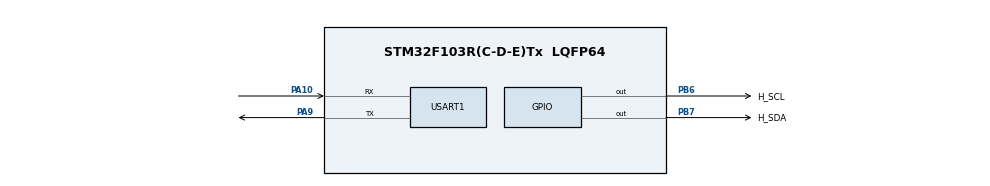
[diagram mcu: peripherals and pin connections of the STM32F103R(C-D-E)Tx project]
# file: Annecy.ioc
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Mcu.Family=STM32F1
Mcu.Name=STM32F103R(C-D-E)Tx
Mcu.Package=LQFP64
NVIC.PriorityGroup=NVIC_PRIORITYGROUP_4
PA10.Mode=Asynchronous
PA10.Signal=USART1_RX
PA13.Mode=Serial_Wire
PA13.Signal=SYS_JTMS-SWDIO
PA14.Mode=Serial_Wire
PA14.Signal=SYS_JTCK-SWCLK
PA9.Mode=Asynchronous
PA9.Signal=USART1_TX
PB6.GPIO_Label=H_SCL
PB6.GPIO_Speed=GPIO_SPEED_FREQ_HIGH
PB6.PinState=GPIO_PIN_SET
PB6.Signal=GPIO_Output
PB7.GPIO_Label=H_SDA
PB7.GPIO_Speed=GPIO_SPEED_FREQ_HIGH
PB7.PinState=GPIO_PIN_SET
PB7.Signal=GPIO_Output
PC14-OSC32_IN.Mode=LSE-External-Oscillator
PC14-OSC32_IN.Signal=RCC_OSC32_IN
PC15-OSC32_OUT.Mode=LSE-External-Oscillator
PC15-OSC32_OUT.Signal=RCC_OSC32_OUT
PD0-OSC_IN.Mode=HSE-External-Oscillator
PD0-OSC_IN.Signal=RCC_OSC_IN
PD1-OSC_OUT.Mode=HSE-External-Oscillator
PD1-OSC_OUT.Signal=RCC_OSC_OUT
ProjectManager.HeapSize=0x200
ProjectManager.StackSize=0x400
ProjectManager.TargetToolchain=MDK-ARM V5
RCC.APB1Freq_Value=8000000
RCC.APB2Freq_Value=8000000
RCC.SYSCLKSource=RCC_SYSCLKSOURCE_PLLCLK
board=Annecy

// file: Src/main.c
/**
  ******************************************************************************
  * File Name          : main.c
  * Description        : Main program body
  ******************************************************************************
  *
  * COPYRIGHT(c) 2017 STMicroelectronics
  *
  * Redistribution and use in source and binary forms, with or without modification,
  * are permitted provided that the following conditions are met:
  *   1. Redistributions of source code must retain the above copyright notice,
  *      this list of conditions and the following disclaimer.
  *   2. Redistributions in binary form must reproduce the above copyright notice,
  *      this list of conditions and the following disclaimer in the documentation
  *      and/or other materials provided with the distribution.
  *   3. Neither the name of STMicroelectronics nor the names of its contributors
  *      may be used to endorse or promote products derived from this software
  *      without specific prior written permission.
  *
  * THIS SOFTWARE IS PROVIDED BY THE COPYRIGHT HOLDERS AND CONTRIBUTORS "AS IS"
  * AND ANY EXPRESS OR IMPLIED WARRANTIES, INCLUDING, BUT NOT LIMITED TO, THE
  * IMPLIED WARRANTIES OF MERCHANTABILITY AND FITNESS FOR A PARTICULAR PURPOSE ARE
  * DISCLAIMED. IN NO EVENT SHALL THE COPYRIGHT HOLDER OR CONTRIBUTORS BE LIABLE
  * FOR ANY DIRECT, INDIRECT, INCIDENTAL, SPECIAL, EXEMPLARY, OR CONSEQUENTIAL
  * DAMAGES (INCLUDING, BUT NOT LIMITED TO, PROCUREMENT OF SUBSTITUTE GOODS OR
  * SERVICES; LOSS OF USE, DATA, OR PROFITS; OR BUSINESS INTERRUPTION) HOWEVER
  * CAUSED AND ON ANY THEORY OF LIABILITY, WHETHER IN CONTRACT, STRICT LIABILITY,
  * OR TORT (INCLUDING NEGLIGENCE OR OTHERWISE) ARISING IN ANY WAY OUT OF THE USE
  * OF THIS SOFTWARE, EVEN IF ADVISED OF THE POSSIBILITY OF SUCH DAMAGE.
  *
  ******************************************************************************
  */
#include "main.h"
#include "stm32f1xx_hal.h"

UART_HandleTypeDef huart1;

/* USER CODE BEGIN PV */
/* Private variables ---------------------------------------------------------*/
#ifdef __GNUC__
/* With GCC, small printf (option LD Linker->Libraries->Small printf
   set to 'Yes') calls __io_putchar() */
#define PUTCHAR_PROTOTYPE int __io_putchar(int ch)
#else
#define PUTCHAR_PROTOTYPE int fputc(int ch, FILE *f)
#endif /* __GNUC__ */
/* USER CODE END PV */

void SystemClock_Config(void);
void Error_Handler(void);
static void MX_GPIO_Init(void);
static void MX_USART1_UART_Init(void);

/* USER CODE BEGIN PFP */
/* Private function prototypes -----------------------------------------------*/
uint16_t temp = 0;
/* USER CODE END PFP */

int main(void)
{

  /* USER CODE BEGIN 1 */
	uint32_t en = 0 ;
	uint32_t sw = 0 ;
  /* USER CODE END 1 */

  /* MCU Configuration----------------------------------------------------------*/

  /* Reset of all peripherals, Initializes the Flash interface and the Systick. */
  HAL_Init();

  /* Configure the system clock */
  SystemClock_Config();

  /* Initialize all configured peripherals */
  MX_GPIO_Init();
  MX_USART1_UART_Init();
	DWT_Init();
//	en = DWT_Get();
//	Delay_us(20);
//	sw = DWT_Get();
//	printf("time=%d\r\n ",(sw - en ));
  /* USER CODE BEGIN 2 */
	printf("hello, world\r\n");
	hdcWriting(0xAA,0xAA,0xAA,0x00);
	hdcWriting(0x40,0x02,0x90,0x00);
//	temp = hdcReading(0x40,0xFB);
//	HAL_Delay(200);
//
//	temp = 0x1521;
//	printf("temp = %x",temp);
  /* USER CODE END 2 */

  /* Infinite loop */
  while (1)
  {

  }

}

/**
  * @brief  Retargets the C library printf function to the USART.
  * @param  None
  * @retval None
  */
PUTCHAR_PROTOTYPE
{
  /* Place your implementation of fputc here */
  /* e.g. write a character to the USART1 and Loop until the end of transmission */
  HAL_UART_Transmit(&huart1, (uint8_t *)&ch, 1, 0xFFFF);

  return ch;
}

/** System Clock Configuration
*/
void SystemClock_Config(void)
{

  RCC_OscInitTypeDef RCC_OscInitStruct;
  RCC_ClkInitTypeDef RCC_ClkInitStruct;

    /**Initializes the CPU, AHB and APB busses clocks
    */
  RCC_OscInitStruct.OscillatorType = RCC_OSCILLATORTYPE_HSI;
  RCC_OscInitStruct.HSIState = RCC_HSI_ON;
  RCC_OscInitStruct.HSICalibrationValue = 16;
  RCC_OscInitStruct.PLL.PLLState = RCC_PLL_ON;
  RCC_OscInitStruct.PLL.PLLSource = RCC_PLLSOURCE_HSI_DIV2;
  RCC_OscInitStruct.PLL.PLLMUL = RCC_PLL_MUL2;
  if (HAL_RCC_OscConfig(&RCC_OscInitStruct) != HAL_OK)
  {
    Error_Handler();
  }

    /**Initializes the CPU, AHB and APB busses clocks
    */
  RCC_ClkInitStruct.ClockType = RCC_CLOCKTYPE_HCLK|RCC_CLOCKTYPE_SYSCLK
                              |RCC_CLOCKTYPE_PCLK1|RCC_CLOCKTYPE_PCLK2;
  RCC_ClkInitStruct.SYSCLKSource = RCC_SYSCLKSOURCE_PLLCLK;
  RCC_ClkInitStruct.AHBCLKDivider = RCC_SYSCLK_DIV1;
  RCC_ClkInitStruct.APB1CLKDivider = RCC_HCLK_DIV1;
  RCC_ClkInitStruct.APB2CLKDivider = RCC_HCLK_DIV1;

  if (HAL_RCC_ClockConfig(&RCC_ClkInitStruct, FLASH_LATENCY_0) != HAL_OK)
  {
    Error_Handler();
  }

    /**Configure the Systick interrupt time
    */
  HAL_SYSTICK_Config(HAL_RCC_GetHCLKFreq()/1000);

    /**Configure the Systick
    */
  HAL_SYSTICK_CLKSourceConfig(SYSTICK_CLKSOURCE_HCLK);

  /* SysTick_IRQn interrupt configuration */
  HAL_NVIC_SetPriority(SysTick_IRQn, 0, 0);
}

/* USART1 init function */
static void MX_USART1_UART_Init(void)
{

  huart1.Instance = USART1;
  huart1.Init.BaudRate = 115200;
  huart1.Init.WordLength = UART_WORDLENGTH_8B;
  huart1.Init.StopBits = UART_STOPBITS_1;
  huart1.Init.Parity = UART_PARITY_NONE;
  huart1.Init.Mode = UART_MODE_TX_RX;
  huart1.Init.HwFlowCtl = UART_HWCONTROL_NONE;
  huart1.Init.OverSampling = UART_OVERSAMPLING_16;
  if (HAL_UART_Init(&huart1) != HAL_OK)
  {
    Error_Handler();
  }

}

/** Configure pins as
        * Analog
        * Input
        * Output
        * EVENT_OUT
        * EXTI
*/
static void MX_GPIO_Init(void)
{

  GPIO_InitTypeDef GPIO_InitStruct;

  /* GPIO Ports Clock Enable */
  __HAL_RCC_GPIOC_CLK_ENABLE();
  __HAL_RCC_GPIOD_CLK_ENABLE();
  __HAL_RCC_GPIOA_CLK_ENABLE();
  __HAL_RCC_GPIOB_CLK_ENABLE();

  /*Configure GPIO pin Output Level */
  HAL_GPIO_WritePin(GPIOB, H_SCL_Pin|H_SDA_Pin, GPIO_PIN_SET);

  /*Configure GPIO pins : H_SCL_Pin H_SDA_Pin */
  GPIO_InitStruct.Pin = H_SCL_Pin|H_SDA_Pin;
  GPIO_InitStruct.Mode = GPIO_MODE_OUTPUT_PP;
  GPIO_InitStruct.Speed = GPIO_SPEED_FREQ_HIGH;
  HAL_GPIO_Init(GPIOB, &GPIO_InitStruct);

}

void Error_Handler(void)
{
  while(1)
  {
  }
}

/************************ (C) COPYRIGHT STMicroelectronics *****END OF FILE****/
